# cmem7 register map
File version: 1.0
Registers are 32-bit, read-write, reset 0x0 unless marked. A register's access mark holds for its fields unless they carry their own. Offsets are from the block's base; [hi:lo] are bit positions; {n}, {i} and the like mark numbered series.

## DDRC — DDR_CFG
Base 0x41400000
0x00 CMD — DDR commands to program
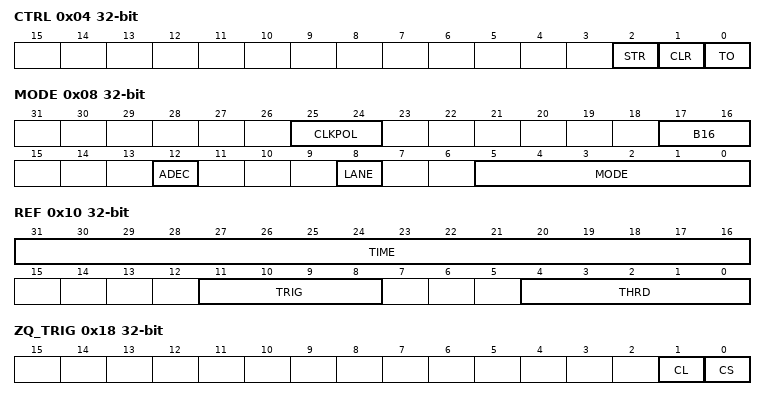
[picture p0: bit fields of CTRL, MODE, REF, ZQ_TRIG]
0x04 CTRL — DDR Control
  [2] STR wo — Start to execute the commands in FIFO
  [1] CLR — Clear commands in FIFO
  [0] TO — Take over DDRC siggen
0x08 MODE — DDR mode
  [25:24] CLKPOL — DQS clkpol set by user on the PHY
  [17:16] B16 — Active 16 bit DQ position when the unmber of DQ IO is 16
  [12] ADEC — address decoder mapping
  [8] LANE — LANE synchronization logic bypass
  [5:0] MODE — DDRC Mode
0x0C QUE — DDRC queue depth
  [0] DEPTH
0x10 REF — Refresh control
  [31:16] TIME — Refresh interval time
  [11:8] TRIG — Number of refresh requests every dl_refi
  [4:0] THRD — Number of refresh requests which can be postponed
0x14 REF_TRIG wo — Refresh trigger
  [0] GO — Write 1 to trigger one refresh request by cbus
0x18 ZQ_TRIG wo — ZQCTL trigger
  [1] CL — Write 1 to trigger one ZQCL request by cbus
  [0] CS — Write 1 to trigger one ZQCS request by cbus
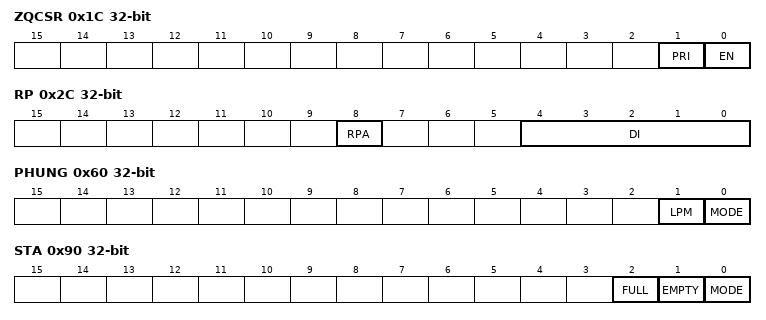
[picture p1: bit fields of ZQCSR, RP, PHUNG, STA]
0x1C ZQCSR
  [1] PRI — 0: DMA access prior to ZQCS, 1: ZQCS prior to DMA access
  [0] EN — Enable ZQCS request
0x20 ZQCSI — ZQCS interval time
0x24 RCD — t(RCD)
  [4:0] DI — t(RCD), delay from ACT command to RW command of same bank
0x28 RAS — t(RAS)
  [5:0] DI — t(RAS), delay from ACT command to PRE command of same bank
0x2C RP — t(RP)
  [8] RPA — 0: t(RP) delay for PREA command; 1: t(RP)+1 delay for PREA command
  [4:0] DI — t(RP), delay from PRE command to ACT/REF/ZQ command
0x30 RC — t(RC)
  [6:0] DI — t(RC), delay from ACT command to ACT command of same bank
0x34 RRD — t(RRD)
  [3:0] DI — t(RRD), delay from ACT command to ACT command
0x38 CCD — t(CCD)
  [2:0] DI — t(CCD), delay from RW command to RW command
0x3C RTW — t(RTW)
  [4:0] DI — t(RTW), delay from RD command to WR command
0x40 WTR — t(WTR)
  [4:0] DI — t(WTR), delay from WR command to RD command
0x44 RTP — t(RTP)
  [2:0] DI — t(RTP), delay from RD command to PRE command of same bank
0x48 WTP — t(WTP)
  [5:0] DI — t(WTP), delay from WR command to PRE command of same bank
0x4C RFC — t(RFC)
  [7:0] DI — t(WTP), delay from WR command to PRE command of same bank
0x50 ZQCL — t(ZQoper)
  [8:0] DI — t(ZQoper), delay from ZQCL command to REF/ZQ/ACT command
0x54 ZQCS — t(ZQCS)
  [6:0] DI — t(ZQCS), delay from ZQCS command to REF/ZQ/ACT command
0x58 FAW — t(FAW)
  [5:0] DI — t(FAW), 4 act command window time
0x5C BURST
  [0] LEN — 0: length 8, 1: length 4
0x60 PHUNG
  [1] LPM — 1: stop the IO clk
  [0] MODE — 0: normal mode, 1: prevent read hang mode
0x64 RL — READ Latency
  [4:0] VAL
0x68 WL — WRITE Latency
  [4:0] VAL
0x6C TRAIN
  [3:0] EN — Enable lane N training mode
{0x70+4i} DQSEN{i} (i=0..2) — Delay cycles of dqsen of byte lane {i}
  [2:0] DL
0x7C DQSEN3 — Delay cycles of dqsen of byte lane 0
  [2:0] DL — Delay cycles of dqsen of byte lane 3
0x80 ODTH — Delay from WR command to odt high transition
  [4:0] DL
0x84 ODTL — Delay from WR command to odt low transition
  [4:0] DL
0x88 ODT wo — Used in write leveling mode
  [0] TRIG — 0: trigger odt low, 1: trigger odt high
0x8C DQS wo — Used in write leveling mode
  [0] TRIG — Writing 1 to this register triggers a dqs pulse
0x90 STA ro — Commands FIFO
  [2] FULL — Sw_proc command fifo full
  [1] EMPTY — Sw_proc command fifo empty
  [0] MODE — DDRC in sw_proc mode
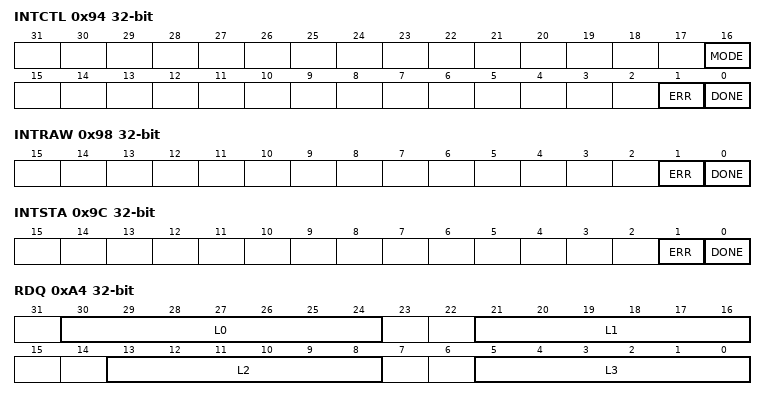
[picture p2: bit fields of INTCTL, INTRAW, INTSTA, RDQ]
0x94 INTCTL — Interrupt Control
  [16] MODE — Interrupt mode: 0: int level active, write 1 to clear; 1: int edge active
  [1] ERR — mask of the lane_sync_error interrupt
  [0] DONE — 0: the sw_proc_done int will not be masked, 1: the sw_proc_done int will be masked
0x98 INTRAW — Interrupt RAW
  [1] ERR — int reg of the lane sync error before masked
  [0] DONE — Int register of sw_proc_done before mask
0x9C INTSTA — Interrupt STA
  [1] ERR — int register of lane sync error after masked
  [0] DONE — Int register of sw_proc_done after mask
0xA0 PHY
  [0] RST — FPGA version, reset read dq fifo. Low active
0xA4 RDQ — FPGA version, read dq delay of byte lane N
  [30:24] L0 — FPGA version, read dq delay of byte lane0
  [21:16] L1 — FPGA version, read dq delay of byte lane3
  [13:8] L2 — FPGA version, read dq delay of byte lane2
  [5:0] L3 — FPGA version, read dq delay of byte lane3
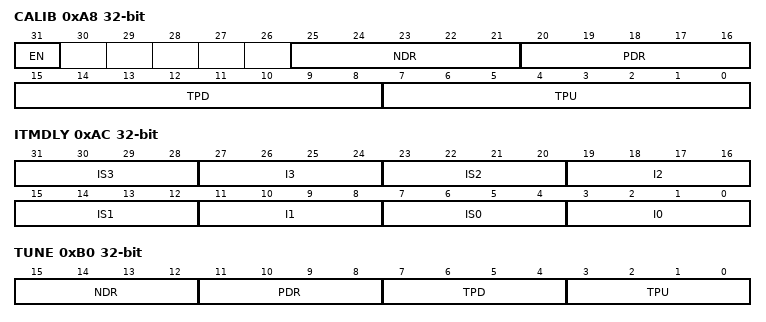
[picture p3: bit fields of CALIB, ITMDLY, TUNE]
0xA8 CALIB ro — calibration
  [31] EN rw — trigger the calibration processing which is sensitive to the positive edge
  [25:21] NDR — calibration result values, if fail then 0x40
  [20:16] PDR — calibration result values, if fail then 0x40
  [15:8] TPD — calibration result values, if fail then 0x40
  [7:0] TPU — calibration result values, if fail then 0x40
0xAC ITMDLY — "itmdly" is the fine delay trim to the read path "dq", "itmsdly" is to the read path of "dqs". From 000 to 111 increasingly, each step is about 40ps
  [8n+7:8n+4] IS{n} (n=0..3) — itmsdly{n}
  [8n+3:8n] I{n} (n=0..3) — itmdly{n}
0xB0 TUNE — CALIB_TUNE
  [15:12] NDR — ndr_tune, tune[2:0] for NDR/PDR, [1:0] is the tune val
  [11:8] PDR — pdr_tune, inial val = tune[2] ? val - tune : val + tune
  [7:4] TPD — tpd_tune, tune[3:0] for TPD/TPU, [2:0] is the tune val
  [3:0] TPU — tpu_tune, finial val = tune[3] ? val - tune : val + tune
0xB4 RD_SEL — RD_WINDOWS_SEL
  [2:0] PHY_SEL — To fix the phy read valid issue, this is to adjust the read data valid window to match the phy read valid by cycle level
